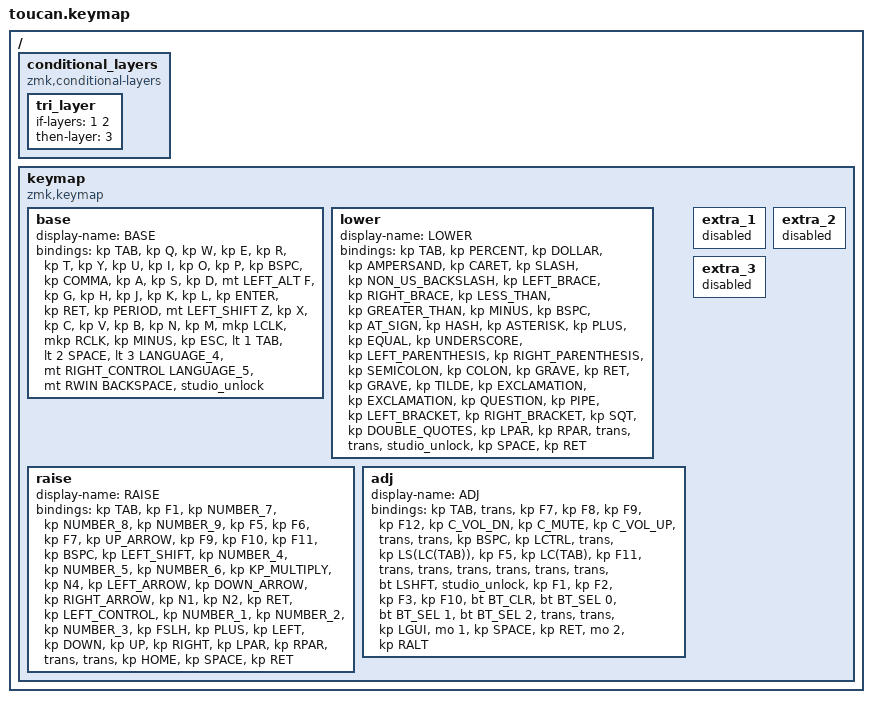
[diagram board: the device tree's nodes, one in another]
#include <behaviors.dtsi>
#include <dt-bindings/zmk/bt.h>
#include <dt-bindings/zmk/keys.h>
#include <dt-bindings/zmk/pointing.h>

#define BASE 0
#define LOWER 1
#define RAISE 2
#define ADJ 3

/ {
    conditional_layers {
        compatible = "zmk,conditional-layers";

        tri_layer {
            if-layers = <1 2>;
            then-layer = <3>;
        };
    };

    keymap {
        compatible = "zmk,keymap";

        /* keyball39 風 Base */

        base {
            display-name = "BASE";
            bindings = <
&kp TAB  &kp Q  &kp W  &kp E  &kp R  &kp T  &kp Y  &kp U  &kp I  &kp O  &kp P  &kp BSPC  &kp COMMA  &kp A  &kp S  &kp D  &mt LEFT_ALT F  &kp G  &kp H  &kp J  &kp K  &kp L  &kp ENTER  &kp RET  &kp PERIOD  &mt LEFT_SHIFT Z  &kp X  &kp C  &kp V  &kp B  &kp N  &kp M  &mkp LCLK  &mkp RCLK  &kp MINUS  &kp ESC  &lt 1 TAB  &lt 2 SPACE  &lt 3 LANGUAGE_4  &mt RIGHT_CONTROL LANGUAGE_5  &mt RWIN BACKSPACE  &studio_unlock
            >;
        };

        /* keyball39 風 Lower: 数字・記号 */

        lower {
            display-name = "LOWER";
            bindings = <
&kp TAB  &kp PERCENT  &kp DOLLAR  &kp AMPERSAND  &kp CARET  &kp SLASH  &kp NON_US_BACKSLASH  &kp LEFT_BRACE  &kp RIGHT_BRACE  &kp LESS_THAN  &kp GREATER_THAN  &kp MINUS  &kp BSPC  &kp AT_SIGN  &kp HASH  &kp ASTERISK  &kp PLUS  &kp EQUAL  &kp UNDERSCORE  &kp LEFT_PARENTHESIS  &kp RIGHT_PARENTHESIS  &kp SEMICOLON  &kp COLON  &kp GRAVE  &kp RET  &kp GRAVE  &kp TILDE  &kp EXCLAMATION  &kp EXCLAMATION  &kp QUESTION  &kp PIPE  &kp LEFT_BRACKET  &kp RIGHT_BRACKET  &kp SQT  &kp DOUBLE_QUOTES  &kp LPAR  &kp RPAR  &trans  &trans  &studio_unlock  &kp SPACE  &kp RET
            >;
        };

        /* keyball39 風 Raise: Fキー・テンキー・矢印 */

        raise {
            display-name = "RAISE";
            bindings = <
&kp TAB  &kp F1  &kp NUMBER_7  &kp NUMBER_8  &kp NUMBER_9  &kp F5  &kp F6  &kp F7  &kp UP_ARROW  &kp F9  &kp F10  &kp F11  &kp BSPC  &kp LEFT_SHIFT  &kp NUMBER_4  &kp NUMBER_5  &kp NUMBER_6  &kp KP_MULTIPLY  &kp N4  &kp LEFT_ARROW  &kp DOWN_ARROW  &kp RIGHT_ARROW  &kp N1  &kp N2  &kp RET  &kp LEFT_CONTROL  &kp NUMBER_1  &kp NUMBER_2  &kp NUMBER_3  &kp FSLH  &kp PLUS  &kp LEFT  &kp DOWN  &kp UP  &kp RIGHT  &kp LPAR  &kp RPAR  &trans  &trans  &kp HOME  &kp SPACE  &kp RET
            >;
        };

        adj {
            display-name = "ADJ";
            bindings = <
&kp TAB  &trans  &kp F7  &kp F8  &kp F9  &kp F12  &kp C_VOL_DN  &kp C_MUTE  &kp C_VOL_UP  &trans  &trans  &kp BSPC  &kp LCTRL  &trans  &kp LS(LC(TAB))  &kp F5  &kp LC(TAB)  &kp F11  &trans  &trans  &trans  &trans  &trans  &trans  &bt LSHFT  &studio_unlock  &kp F1  &kp F2  &kp F3  &kp F10  &bt BT_CLR  &bt BT_SEL 0  &bt BT_SEL 1  &bt BT_SEL 2  &trans  &trans  &kp LGUI  &mo 1  &kp SPACE  &kp RET  &mo 2  &kp RALT
            >;
        };

        extra_1 { status = "reserved"; };

        extra_2 { status = "reserved"; };

        extra_3 { status = "reserved"; };
    };
};
